# RE01_1500KB register map
Vendor: Renesas Electronics Corporation; Series: RE01_1500KB; File version: 1.20
CPU: CM0PLUS r0p1, little endian, MPU, no FPU, VTOR, 2 interrupt priority bits
Registers are 8-bit, read-write, reset 0x0 unless marked. A register's access mark holds for its fields unless they carry their own. Offsets are from the block's base; [hi:lo] are bit positions; {n}, {i} and the like mark numbered series; 'fields as' and 'values as' point back to an identical list.

## FLASH
Base 0x01008000; alternate view of TEMPS
{0x190+4i} UIDR{i} (i=0..3) 32-bit ro reset not defined — Unique ID Register {i}
0x3F01411C FLWT — Flash Wait Cycle Register
  [2:0] FLWT — Flash Wait Cycle.
    0=0 wait; 1=1 wait
0x3F016416 FWEPROR reset 0x2 — Flash Write/Erase Protect Register
  [1:0] FLWE — Flash Programming and Erasure.
    0=Prohibits programming and erasure of the code flash; 1=Permits programming and erasure of the code flash; 2=Prohibits programming and erasure of the code flash; 3=Prohibits programming and erasure of the code flash
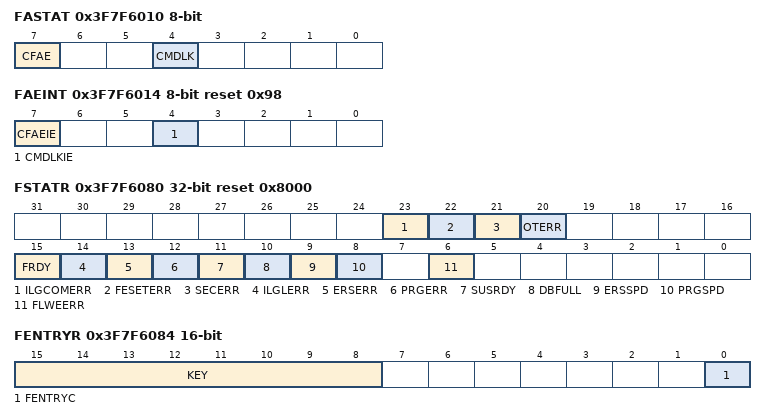
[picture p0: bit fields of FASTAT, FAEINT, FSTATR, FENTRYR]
0x3F7F6010 FASTAT — Flash Access Status Register
  [7] CFAE — Code Flash Memory Access Violation Flag.
    0=No Code flash memory access violation has occurred; 1=A code Flash memory access violation has occurred
  [4] CMDLK ro — Command Lock Flag.
    0=The flash sequencer is not in the command-locked state; 1=The flash sequencer is in the command-locked state
0x3F7F6014 FAEINT reset 0x98 — Flash Access Error Interrupt Enable Register
  [7] CFAEIE — Code Flash Memory Access Violation Interrupt Enable.
    0=Generation of an FCU_FIFERR interrupt request is disabled when FASTAT.CFAE is set to 1; 1=Generation of an FCU_FIFERR interrupt request is enabled when FASTAT.CFAE is set to 1
  [4] CMDLKIE — Command Lock Interrupt Enable.
    0=Generation of an FCU_FIFERR interrupt request is disabled when FASTAT.CMDLK is set to 1; 1=Generation of an FCU_FIFERR interrupt request is enabled when FASTAT.CMDLK is set to 1
0x3F7F6018 FRDYIE — Flash Access Error Interrupt Enable Register
  [0] FRDYIE — Flash Ready Interrupt Enable.
    0=Generation of an FCU_FRDYI interrupt request is disabled when FSTAT.FRDY is change to 1 from 0; 1=Generation of an FRDY interrupt request is enabled when FSTAT.FRDY is change to 1 from 0
0x3F7F6030 FSADDR 32-bit — FACI Command Start Address Register
0x3F7F6080 FSTATR 32-bit ro reset 0x8000 — Flash Status Register
  [23] ILGCOMERR — Illegal Command Error Flag.
    0=An error has not been detected; 1=An error has been detected
  [22] FESETERR — FENTRY Setting Error Flag.
    values as ILGCOMERR
  [21] SECERR — Security Error Flag.
    values as ILGCOMERR
  [20] OTERR — Other Error Flag.
    values as ILGCOMERR
  [15] FRDY — Flash Ready Flag.
    0=Program, Block Erase, P/E suspend, P/E resume, forced stop or configuration set command processing is in progress; 1=None of the above is in progress
  [14] ILGLERR — Illegal Error Flag.
    0=The flash sequencer has not detected an illegal FACI command or illegal flash memory access; 1=The flash sequencer has detected an illegal FACI command or illegal flash memory access
  [13] ERSERR — Erasure Error Flag.
    0=Erasure has been completed successfully; 1=An Error has occurred during erasure
  [12] PRGERR — Programming Error Flag.
    0=Programming has been completed successfully; 1=An error has occurred during programming
  [11] SUSRDY — Suspend Ready Flag.
    0=The flash sequencer cannot receive P/E suspend commands; 1=The flash sequencer can receive P/E suspend commands
  [10] DBFULL — Data Buffer Full Flag.
    0=The data buffer is empty; 1=The data buffer is full
  [9] ERSSPD — Erasure Suspend Status Flag.
    0=The flash sequencer is in a state other than those corresponding to the value 1; 1=The flash sequencer is in the erasure suspension processing state or the erasure-suspended state
  [8] PRGSPD — Programming Suspend Status Flag.
    0=The flash sequencer is in a state other than those corresponding to the value 1; 1=The flash sequencer is in the programming suspension processing state or the programming suspended state
  [6] FLWEERR — Flash Write/Erase Protect Error Flag.
    0=An error has not occurred; 1=An error has occurred
0x3F7F6084 FENTRYR 16-bit — Flash P/E Mode Entry Register
  [15:8] KEY — Key Code
  [0] FENTRYC — Code Flash P/E Mode Entry.
    0=Code flash is in read mode; 1=Code flash is in P/E mode
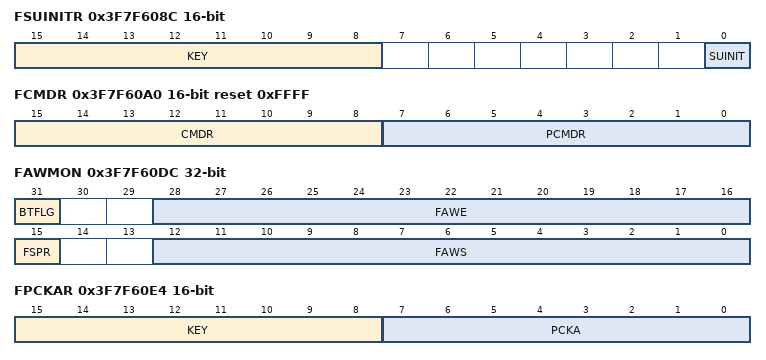
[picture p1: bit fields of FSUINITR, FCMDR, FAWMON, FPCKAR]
0x3F7F608C FSUINITR 16-bit — Flash Sequencer Set-Up Initialization Register
  [15:8] KEY — Key Code
  [0] SUINIT — Set-Up Initialization.
    0=The FEADDR, FSADDR, FENTRYR, and FBCCNT flash sequencer set-up registers keep their current calues; 1=The FEADDR, FSADDR, FENTRYR, and FBCCNT flash sequencer set-up registers are initialized
0x3F7F60A0 FCMDR 16-bit ro reset 0xFFFF — FACI Command Register
  [15:8] CMDR — The lastest command is stored.
  [7:0] PCMDR — The command just before the lastest command is stored.
0x3F7F60DC FAWMON 32-bit ro (reset mask 0x70007000) — Flash Access Window Monitor Register
  [31] BTFLG — Flag of Start-Up Area select for Boot Swap.
    0=The start-up area is the alternate block (block 1); 1=The start-up area is the default block (block 0)
  [28:16] FAWE — End Block Address of Access Window.
  [15] FSPR — Protection Flag of programming to set Access Window, Boot Flag and Start-up Area Control, Configuration Clear command execution
    0=Protected state; 1=Non-protected state
  [12:0] FAWS — Start Block Address of Access Window.
0x3F7F60E4 FPCKAR 16-bit (reset mask 0xFF00) — Flash Sequencer Processing Clock Notification Register
  [15:8] KEY — Key Code
  [7:0] PCKA — Flash Sequencer Operating Clock Notification.
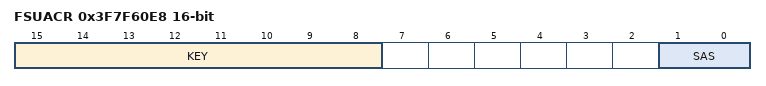
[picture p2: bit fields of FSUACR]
0x3F7F60E8 FSUACR 16-bit (reset mask 0xFFFC) — Flash Start-up Area Control Register
  [15:8] KEY — Key Code
  [1:0] SAS — Start Up Area Select
    0=X: Start-up area is selected by BTFLG bit; 2=Start-up area is temporaryly switched to the default area (block 0); 3=Start-up Area is temporarily switched to the alternate area (block 1)
